# HC32M413 register map
File version: 1.0
CPU: CM4 r0p1, little endian, MPU, FPU, 4 interrupt priority bits
Registers are 32-bit, read-write, reset 0x0 unless marked. A register's access mark holds for its fields unless they carry their own. Offsets are from the block's base; lines under a group give offsets from that group; [hi:lo] are bit positions; {n}, {i} and the like mark numbered series; 'fields as' and 'values as' point back to an identical list; <NAME> marks a mode.

## Memory map
0x00020000 ICG size 0x14
0x40010400 EFM size 0x289
0x40010800 AOS size 0x40
0x40015000 TMRA1 size 0x146 — desc TMRA
0x40015400 TMRA2 size 0x146 — desc TMRA
0x40015800 TMRA3 size 0x146 — desc TMRA
0x40015C00 TMRA4 size 0x146 — desc TMRA
0x40016000 TMRA5 size 0x156
0x40017000 TMR4 size 0x110
0x40017C00 EMB0 size 0x1C — desc EMB
0x40017C20 EMB1 size 0x1C — desc EMB
0x4001C000 SPI size 0x1C
0x4001D000 USART1 size 0x1C — desc USART
0x4001D400 USART2 size 0x20 — desc USART
0x4001E800 HALL size 0x34
0x40021000 USART3 size 0x20 — desc USART
0x40021400 USART4 size 0x20 — desc USART
0x40024000 TMR01 size 0x18 — desc TMR0
0x40024400 TMR02 size 0x18 — desc TMR0
0x40030000 ADC size 0xC4
0x40048400 FCM size 0x24
0x40049000 WDT size 0xC
0x40049400 SWDT size 0xC
0x4004A000 CMP1 size 0x20 — desc CMP
0x4004A000 CMP_COMMON size 0x10
0x4004A100 CMP2 size 0x20 — desc CMP
0x4004A400 CMP3 size 0x20 — desc CMP
0x4004E000 I2C size 0x3C
0x40050400 CRC size 0x100
0x40051000 INTC size 0x2AC
0x40052000 DCU size 0x1C
0x40053000 DMA size 0x138
0x40053800 GPIO size 0x5CC
0x40054000 PWC size 0x54
0x40054100 RMU size 0x8
0x40054400 CMU size 0x49
0x40054800 MAU size 0x2C
0x40054C00 PERIC size 0x20
0xE0042000 DBGC size 0x40

## Interrupts
70 FCM — Frequency measurement interrupt

## ADC
Base 0x40030000
0x00 STR 8-bit
  [0] STRT
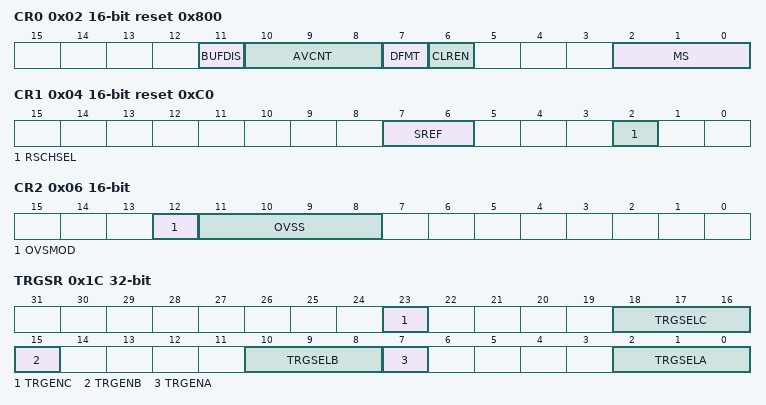
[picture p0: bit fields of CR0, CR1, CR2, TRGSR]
0x02 CR0 16-bit reset 0x800
  [11] BUFDIS, [10:8] AVCNT, [7] DFMT, [6] CLREN, [2:0] MS
0x04 CR1 16-bit reset 0xC0
  [7:6] SREF, [2] RSCHSEL
0x06 CR2 16-bit
  [12] OVSMOD, [11:8] OVSS
0x0C CHSELRA
  [16:0] CHSELA
0x10 CHSELRB
  [16:0] CHSELB
0x14 AVCHSELR
  [16:0] AVCHSEL
0x1C TRGSR
  [23] TRGENC, [18:16] TRGSELC, [15] TRGENB, [10:8] TRGSELB, [7] TRGENA, [2:0] TRGSELA
{0x20+i} SSTR{i} 8-bit reset 0x4 (i=0..16)
0x40 CHSELRC
  [16:0] CHSELC
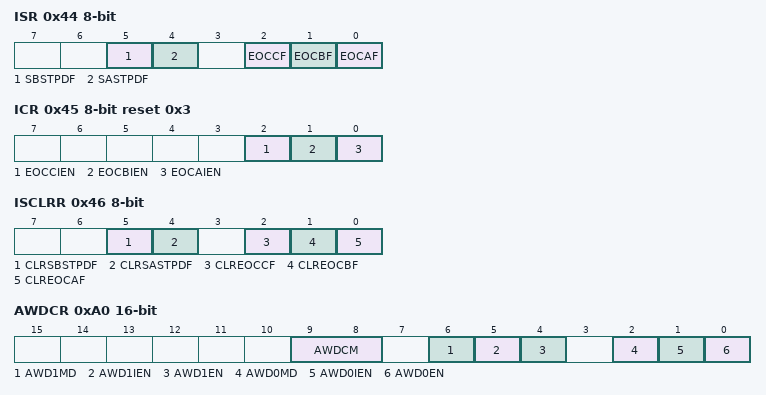
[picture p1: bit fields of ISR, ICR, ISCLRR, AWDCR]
0x44 ISR 8-bit ro
  [5] SBSTPDF, [4] SASTPDF, [2] EOCCF, [1] EOCBF, [0] EOCAF
0x45 ICR 8-bit reset 0x3
  [2] EOCCIEN, [1] EOCBIEN, [0] EOCAIEN
0x46 ISCLRR 8-bit wo
  [5] CLRSBSTPDF, [4] CLRSASTPDF, [2] CLREOCCF, [1] CLREOCBF, [0] CLREOCAF
{0x50+2i} DR{i} 16-bit ro (i=0..16)
0xA0 AWDCR 16-bit
  [9:8] AWDCM, [6] AWD1MD, [5] AWD1IEN, [4] AWD1EN, [2] AWD0MD, [1] AWD0IEN, [0] AWD0EN
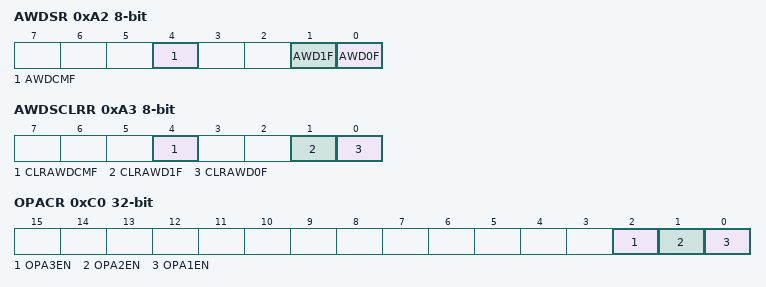
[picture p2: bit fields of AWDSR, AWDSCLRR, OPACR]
0xA2 AWDSR 8-bit ro
  [4] AWDCMF, [1] AWD1F, [0] AWD0F
0xA3 AWDSCLRR 8-bit
  [4] CLRAWDCMF, [1] CLRAWD1F, [0] CLRAWD0F
0xA4 AWD0DR0 16-bit
0xA6 AWD0DR1 16-bit reset 0xFFFF
0xA8 AWD0CHSR 8-bit
  [4:0] AWDCH
0xAC AWD1DR0 16-bit
0xAE AWD1DR1 16-bit reset 0xFFFF
0xB0 AWD1CHSR 8-bit
  [4:0] AWDCH
0xC0 OPACR
  [2] OPA3EN, [1] OPA2EN, [0] OPA1EN

## AOS
Base 0x40010800
0x00 INTSFTTRG wo
  [0] STRG
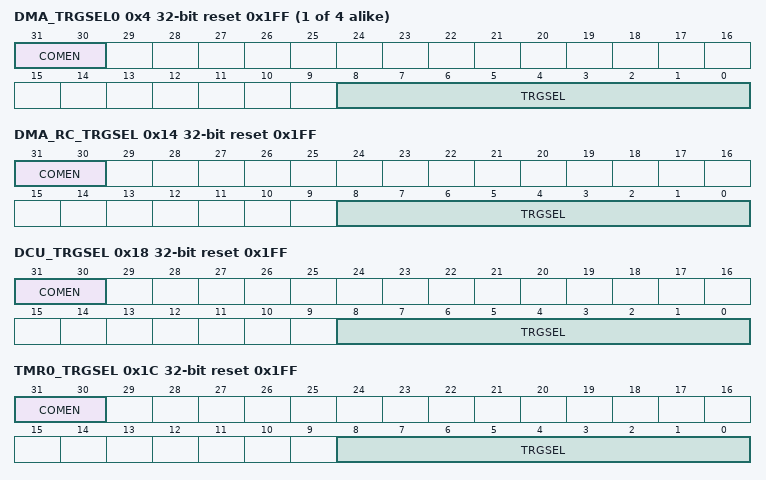
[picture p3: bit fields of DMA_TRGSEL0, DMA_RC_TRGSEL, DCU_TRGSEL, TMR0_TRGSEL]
{0x4+4i} DMA_TRGSEL{i} reset 0x1FF (i=0..3)
  [31:30] COMEN, [8:0] TRGSEL
0x14 DMA_RC_TRGSEL reset 0x1FF
  [31:30] COMEN, [8:0] TRGSEL
0x18 DCU_TRGSEL reset 0x1FF
  [31:30] COMEN, [8:0] TRGSEL
0x1C TMR0_TRGSEL reset 0x1FF
  [31:30] COMEN, [8:0] TRGSEL
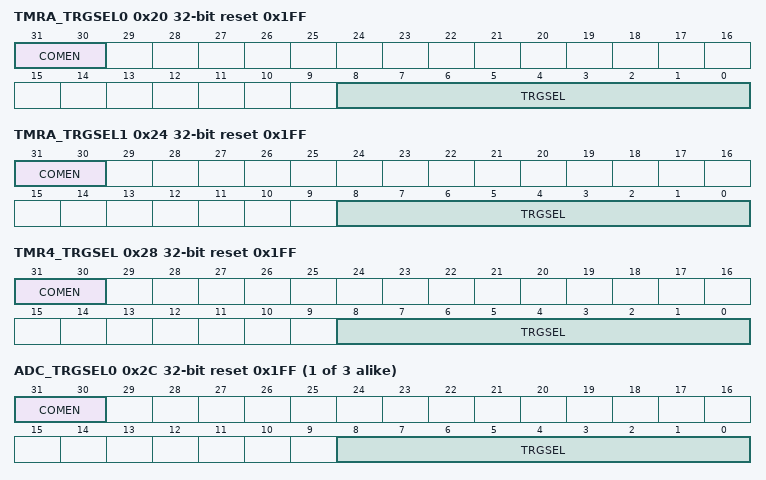
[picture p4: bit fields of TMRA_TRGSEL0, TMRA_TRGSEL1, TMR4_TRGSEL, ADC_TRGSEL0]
0x20 TMRA_TRGSEL0 reset 0x1FF
  [31:30] COMEN, [8:0] TRGSEL
0x24 TMRA_TRGSEL1 reset 0x1FF
  [31:30] COMEN, [8:0] TRGSEL
0x28 TMR4_TRGSEL reset 0x1FF
  [31:30] COMEN, [8:0] TRGSEL
{0x2C+4i} ADC_TRGSEL{i} reset 0x1FF (i=0..2)
  [31:30] COMEN, [8:0] TRGSEL
0x38 COMTRGSEL1 reset 0x1FF
  [8:0] COMTRG
0x3C COMTRGSEL2 reset 0x1FF
  [8:0] COMTRG

## CMP1 — desc CMP
Base 0x4004A000
Same registers: CMP2 0x4004A100, CMP3 0x4004A400
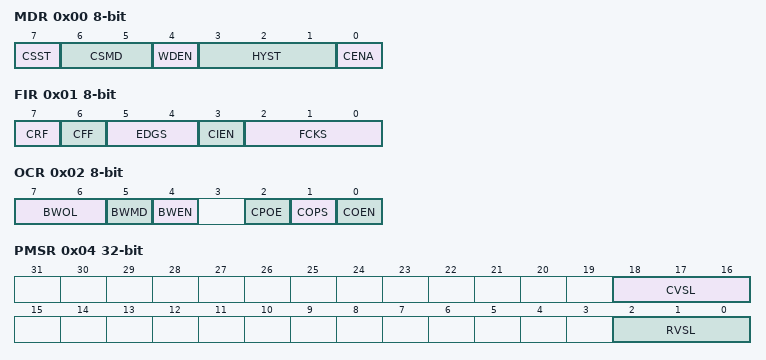
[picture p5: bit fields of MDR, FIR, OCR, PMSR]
0x00 MDR 8-bit
  [7] CSST, [6:5] CSMD, [4] WDEN, [3:1] HYST, [0] CENA
0x01 FIR 8-bit
  [7] CRF, [6] CFF, [5:4] EDGS, [3] CIEN, [2:0] FCKS
0x02 OCR 8-bit
  [7:6] BWOL, [5] BWMD, [4] BWEN, [2] CPOE, [1] COPS, [0] COEN
0x03 OMR 8-bit ro
  [0] CMON
0x04 PMSR
  [18:16] CVSL, [2:0] RVSL
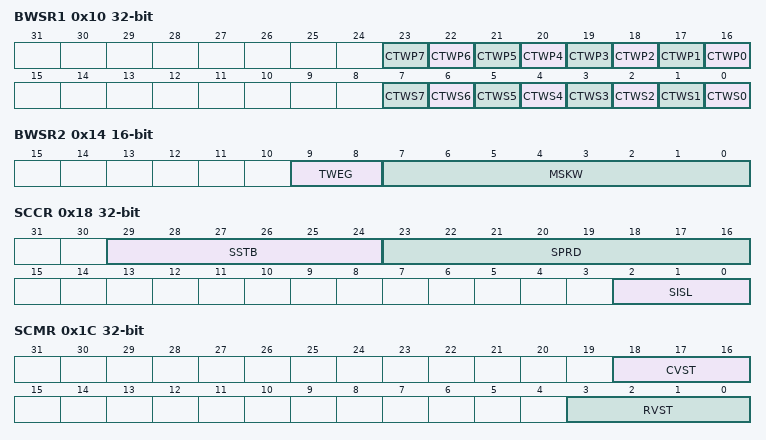
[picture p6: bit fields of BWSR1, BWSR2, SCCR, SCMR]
0x10 BWSR1
  [n+16] CTWP{n} (n=0..7), [n] CTWS{n} (n=0..7)
0x14 BWSR2 16-bit
  [9:8] TWEG, [7:0] MSKW
0x18 SCCR
  [29:24] SSTB, [23:16] SPRD, [2:0] SISL
0x1C SCMR
  [18:16] CVST, [3:0] RVST
